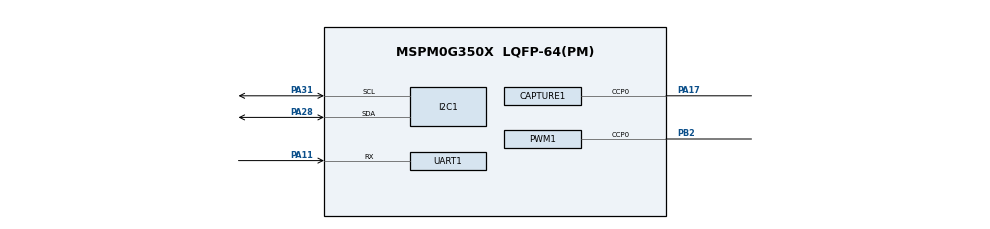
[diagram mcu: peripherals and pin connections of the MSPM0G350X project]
/**
 * @cliArgs --device "MSPM0G350X" --package "LQFP-64(PM)" --part "Default" --product "mspm0_sdk@2.01.00.03"
 * @versions {"tool":"1.20.0+3587"}
 */

/**
 * Import the modules used in this configuration.
 */
const ADC12         = scripting.addModule("/ti/driverlib/ADC12", {}, false);
const ADC121        = ADC12.addInstance();
const CAPTURE       = scripting.addModule("/ti/driverlib/CAPTURE", {}, false);
const CAPTURE1      = CAPTURE.addInstance();
const CAPTURE2      = CAPTURE.addInstance();
const GPIO          = scripting.addModule("/ti/driverlib/GPIO", {}, false);
const GPIO1         = GPIO.addInstance();
const GPIO2         = GPIO.addInstance();
const GPIO3         = GPIO.addInstance();
const GPIO4         = GPIO.addInstance();
const I2C           = scripting.addModule("/ti/driverlib/I2C", {}, false);
const I2C1          = I2C.addInstance();
const PWM           = scripting.addModule("/ti/driverlib/PWM", {}, false);
const PWM1          = PWM.addInstance();
const SYSCTL        = scripting.addModule("/ti/driverlib/SYSCTL");
const TIMER         = scripting.addModule("/ti/driverlib/TIMER", {}, false);
const TIMER1        = TIMER.addInstance();
const TIMER2        = TIMER.addInstance();
const UART          = scripting.addModule("/ti/driverlib/UART", {}, false);
const UART1         = UART.addInstance();
const ProjectConfig = scripting.addModule("/ti/project_config/ProjectConfig");

/**
 * Write custom configuration values to the imported modules.
 */
const multiplier2         = system.clockTree["PLL_QDIV"];
multiplier2.multiplyValue = 6;

const pinFunction3     = system.clockTree["HFCLKEXT"];
pinFunction3.inputFreq = 40;

const pinFunction4     = system.clockTree["HFXT"];
pinFunction4.inputFreq = 24;

ADC121.$name                             = "ADC12_0";
ADC121.repeatMode                        = true;
ADC121.configureDMA                      = true;
ADC121.enabledInterrupts                 = ["DL_ADC12_INTERRUPT_DMA_DONE"];
ADC121.enableFIFO                        = true;
ADC121.sampleTime0                       = "62.5ns";
ADC121.powerDownMode                     = "DL_ADC12_POWER_DOWN_MODE_MANUAL";
ADC121.sampCnt                           = 6;
ADC121.endAdd                            = 1;
ADC121.adcMem1chansel                    = "DL_ADC12_INPUT_CHAN_1";
ADC121.enabledDMATriggers                = ["DL_ADC12_DMA_MEM10_RESULT_LOADED"];
ADC121.trigSrc                           = "DL_ADC12_TRIG_SRC_EVENT";
ADC121.subChanID                         = 1;
ADC121.adcMem0trig                       = "DL_ADC12_TRIGGER_MODE_TRIGGER_NEXT";
ADC121.peripheral.adcPin0.$assign        = "PA27";
ADC121.adcPin0Config.$name               = "ti_driverlib_gpio_GPIOPinGeneric3";
ADC121.DMA_CHANNEL.$name                 = "DMA_CH0";
ADC121.DMA_CHANNEL.addressMode           = "f2b";
ADC121.DMA_CHANNEL.configureTransferSize = true;
ADC121.DMA_CHANNEL.transferSize          = 512;

const Board = scripting.addModule("/ti/driverlib/Board", {}, false);

CAPTURE1.$name                      = "CAPTURE_0";
CAPTURE1.interruptPriority          = "1";
CAPTURE1.captMode                   = "COMBINED";
CAPTURE1.interrupts                 = ["CC0_DN","CC1_DN"];
CAPTURE1.timerPeriod                = "2.04ms";
CAPTURE1.peripheral.$assign         = "TIMA1";
CAPTURE1.peripheral.ccp0Pin.$assign = "PA17";
CAPTURE1.ccp0PinConfig.$name        = "ti_driverlib_gpio_GPIOPinGeneric6";

CAPTURE2.$name               = "CAPTURE_1";
CAPTURE2.ccp0PinConfig.$name = "ti_driverlib_gpio_GPIOPinGeneric7";

GPIO1.$name                               = "GPIO_led";
GPIO1.associatedPins.create(2);
GPIO1.associatedPins[0].$name             = "PIN_0";
GPIO1.associatedPins[0].launchPadShortcut = "LED1En";
GPIO1.associatedPins[0].initialValue      = "SET";
GPIO1.associatedPins[1].$name             = "PIN_22";
GPIO1.associatedPins[1].launchPadShortcut = "LED2BlueEn";

GPIO2.$name                               = "GPIO_key";
GPIO2.associatedPins.create(2);
GPIO2.associatedPins[0].launchPadShortcut = "Button2En";
GPIO2.associatedPins[0].$name             = "PIN_18";
GPIO2.associatedPins[0].internalResistor  = "PULL_DOWN";
GPIO2.associatedPins[1].launchPadShortcut = "Button3En";
GPIO2.associatedPins[1].$name             = "PIN_21";

GPIO3.$name                          = "GPIO_ADF";
GPIO3.associatedPins.create(4);
GPIO3.associatedPins[0].$name        = "PIN_CLK";
GPIO3.associatedPins[0].assignedPort = "PORTB";
GPIO3.associatedPins[0].assignedPin  = "6";
GPIO3.associatedPins[1].$name        = "PIN_DATA";
GPIO3.associatedPins[1].assignedPort = "PORTB";
GPIO3.associatedPins[1].assignedPin  = "0";
GPIO3.associatedPins[2].assignedPort = "PORTB";
GPIO3.associatedPins[2].assignedPin  = "16";
GPIO3.associatedPins[2].$name        = "PIN_LE";
GPIO3.associatedPins[3].$name        = "PIN_CE";
GPIO3.associatedPins[3].assignedPort = "PORTA";
GPIO3.associatedPins[3].assignedPin  = "13";

GPIO4.$name                          = "GPIO_SPI";
GPIO4.associatedPins.create(3);
GPIO4.associatedPins[0].$name        = "PIN_CS";
GPIO4.associatedPins[0].direction    = "INPUT";
GPIO4.associatedPins[0].assignedPort = "PORTB";
GPIO4.associatedPins[0].assignedPin  = "19";
GPIO4.associatedPins[0].polarity     = "FALL";
GPIO4.associatedPins[0].interruptEn  = true;
GPIO4.associatedPins[1].$name        = "PIN_CK";
GPIO4.associatedPins[1].direction    = "INPUT";
GPIO4.associatedPins[1].assignedPort = "PORTA";
GPIO4.associatedPins[1].assignedPin  = "22";
GPIO4.associatedPins[1].interruptEn  = true;
GPIO4.associatedPins[1].polarity     = "RISE";
GPIO4.associatedPins[2].$name        = "PIN_DA";
GPIO4.associatedPins[2].direction    = "INPUT";
GPIO4.associatedPins[2].assignedPort = "PORTB";
GPIO4.associatedPins[2].assignedPin  = "18";
GPIO4.associatedPins[2].polarity     = "RISE_FALL";

I2C1.$name                           = "I2C_0";
I2C1.basicEnableController           = true;
I2C1.basicControllerStandardBusSpeed = "Fast";
I2C1.peripheral.$assign              = "I2C0";
I2C1.peripheral.sdaPin.$assign       = "PA28";
I2C1.peripheral.sclPin.$assign       = "PA31";
I2C1.sdaPinConfig.$name              = "ti_driverlib_gpio_GPIOPinGeneric0";
I2C1.sclPinConfig.$name              = "ti_driverlib_gpio_GPIOPinGeneric1";

PWM1.$name                      = "PWM_0";
PWM1.ccIndex                    = [0];
PWM1.clockDivider               = 8;
PWM1.timerCount                 = 10000;
PWM1.peripheral.$assign         = "TIMG6";
PWM1.peripheral.ccp0Pin.$assign = "PB2";
PWM1.PWM_CHANNEL_0.$name        = "ti_driverlib_pwm_PWMTimerCC0";
PWM1.PWM_CHANNEL_0.dutyCycle    = 50;
PWM1.ccp0PinConfig.$name        = "ti_driverlib_gpio_GPIOPinGeneric2";

SYSCTL.forceDefaultClkConfig = true;
SYSCTL.clockTreeEn           = true;
SYSCTL.useHFCLK_Manual       = true;
SYSCTL.HFCLKSource           = "HFXT";
SYSCTL.HFCLK_Freq            = 24000000;

TIMER1.$name              = "TIMER_0";
TIMER1.timerClkDiv        = 5;
TIMER1.timerClkPrescale   = 256;
TIMER1.interrupts         = ["ZERO"];
TIMER1.interruptPriority  = "3";
TIMER1.timerMode          = "PERIODIC";
TIMER1.timerPeriod        = "1 s";
TIMER1.peripheral.$assign = "TIMG0";

TIMER2.$name                       = "TIMER_ADC";
TIMER2.timerMode                   = "PERIODIC";
TIMER2.timerStartTimer             = true;
TIMER2.event1PublisherChannel      = 1;
TIMER2.event1ControllerInterruptEn = ["ZERO_EVENT"];
TIMER2.timerPeriod                 = "1us";

UART1.$name                    = "UART_0";
UART1.uartClkDiv               = "2";
UART1.enabledInterrupts        = ["RX"];
UART1.peripheral.rxPin.$assign = "PA11";
UART1.txPinConfig.$name        = "ti_driverlib_gpio_GPIOPinGeneric4";
UART1.rxPinConfig.$name        = "ti_driverlib_gpio_GPIOPinGeneric5";

ProjectConfig.genLibCMSIS = true;

/**
 * Pinmux solution for unlocked pins/peripherals. This ensures that minor changes to the automatic solver in a future
 * version of the tool will not impact the pinmux you originally saw.  These lines can be completely deleted in order to
 * re-solve from scratch.
 */
ADC121.peripheral.$suggestSolution             = "ADC0";
ADC121.DMA_CHANNEL.peripheral.$suggestSolution = "DMA_CH0";
Board.peripheral.$suggestSolution              = "DEBUGSS";
Board.peripheral.swclkPin.$suggestSolution     = "PA20";
Board.peripheral.swdioPin.$suggestSolution     = "PA19";
CAPTURE2.peripheral.$suggestSolution           = "TIMG7";
CAPTURE2.peripheral.ccp0Pin.$suggestSolution   = "PA23";
GPIO1.associatedPins[0].pin.$suggestSolution   = "PA0";
GPIO1.associatedPins[1].pin.$suggestSolution   = "PB22";
GPIO2.associatedPins[0].pin.$suggestSolution   = "PA18";
GPIO2.associatedPins[1].pin.$suggestSolution   = "PB21";
GPIO3.associatedPins[0].pin.$suggestSolution   = "PB6";
GPIO3.associatedPins[1].pin.$suggestSolution   = "PB0";
GPIO3.associatedPins[2].pin.$suggestSolution   = "PB16";
GPIO3.associatedPins[3].pin.$suggestSolution   = "PA13";
GPIO4.associatedPins[0].pin.$suggestSolution   = "PB19";
GPIO4.associatedPins[1].pin.$suggestSolution   = "PA22";
GPIO4.associatedPins[2].pin.$suggestSolution   = "PB18";
TIMER2.peripheral.$suggestSolution             = "TIMA0";
UART1.peripheral.$suggestSolution              = "UART0";
UART1.peripheral.txPin.$suggestSolution        = "PA10";
